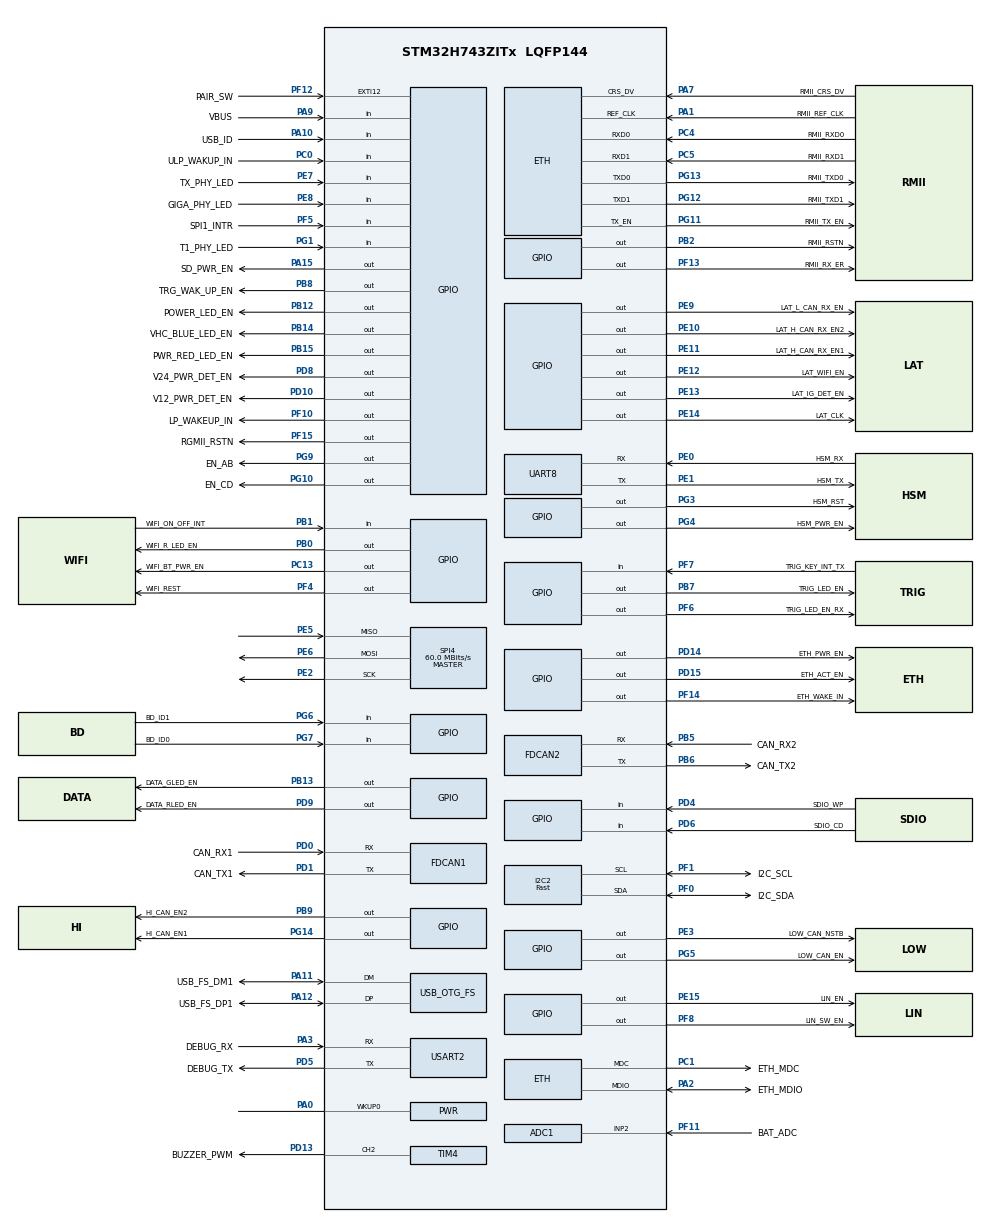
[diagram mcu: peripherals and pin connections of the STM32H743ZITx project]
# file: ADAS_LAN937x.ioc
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PA11.GPIO_Speed=GPIO_SPEED_FREQ_HIGH
IWDG1.Prescaler=IWDG_PRESCALER_16
VP_SYS_VS_tim6.Mode=TIM6
SPI4.VirtualType=VM_MASTER
VP_TIM17_VS_ClockSourceINT.Mode=Enable_Timer
FDCAN2.DataPrescaler=2
NVIC.TIM6_DAC_IRQn=true\:0\:0\:false\:false\:true\:false\:false\:true
PG4.Signal=GPIO_Output
PB14.GPIO_Label=VHC_BLUE_LED_EN
PG6.GPIO_Label=BD_ID1
FDCAN2.RxFifo0ElmtsNbr=32
RCC.PLLFRACN=0
VP_RTC_VS_RTC_Activate.Mode=RTC_Enabled
PB6.GPIO_Label=CAN_TX2
PA15\ (JTDI).Signal=GPIO_Output
PC5.Mode=RMII
PB13.Signal=GPIO_Output
PD6.GPIO_Label=SDIO_CD
PG13.Signal=ETH_TXD0
PF6.GPIO_Label=TRIG_LED_EN_RX
RCC.SYSCLKSource=RCC_SYSCLKSOURCE_PLLCLK
IWDG1.Reload=762
FREERTOS.configENABLE_FPU=1
PA14\ (JTCK/SWCLK).Signal=DEBUG_JTCK-SWCLK
PF7.Signal=GPIO_Input
PE2.Mode=Full_Duplex_Master
PD4.Signal=GPIO_Input
I2C2.I2C_Speed_Mode=I2C_Fast
PB6.Signal=FDCAN2_TX
PB6.Mode=FDCANFD
PD0.Signal=FDCAN1_RX
PD8.Signal=GPIO_Output
PE5.Signal=SPI4_MISO
PE1.Signal=UART8_TX
PF10.GPIO_Label=LP_WAKEUP_IN
PB2.Signal=GPIO_Output
PF1.GPIO_Label=I2C_SCL
RCC.DIVM3=5
RCC.DIVM2=5
RCC.DIVM1=5
RCC.RTCClockSelection=RCC_RTCCLKSOURCE_LSE
PD1.GPIO_Label=CAN_TX1
PB12.GPIO_Label=POWER_LED_EN
PF12.GPIO_Label=PAIR_SW
PC4.GPIO_Label=RMII_RXD0
PE9.Signal=GPIO_Output
PD1.GPIO_Speed=GPIO_SPEED_FREQ_VERY_HIGH
PB1.GPIO_Label=WIFI_ON_OFF_INT
FDCAN1.NominalPrescaler=2
PG4.GPIO_Label=HSM_PWR_EN
PA0.Mode=WakeUp0
SH.S_TIM4_CH2.0=TIM4_CH2,PWM Generation2 CH2
PE2.Signal=SPI4_SCK
PA14\ (JTCK/SWCLK).Mode=Trace_Asynchronous_SW
TIM4.Period=0
VP_FREERTOS_VS_CMSIS_V1.Mode=CMSIS_V1
PF1.GPIO_Speed=GPIO_SPEED_FREQ_HIGH
PE10.Signal=GPIO_Output
ADC1.SamplingTime-0\#ChannelRegularConversion=ADC_SAMPLETIME_1CYCLE_5
PA0.Signal=PWR_WKUP0
Mcu.Package=LQFP144
PB9.Signal=GPIO_Output
PB1.Signal=GPIO_Input
NVIC.TimeBase=TIM6_DAC_IRQn
RCC.PLL3FRACN=0
NVIC.TimeBaseIP=TIM6
PA10.Signal=GPIO_Input
PE12.GPIO_Label=LAT_WIFI_EN
FDCAN2.TxElmtSize=FDCAN_DATA_BYTES_64
PB5.GPIO_Speed=GPIO_SPEED_FREQ_VERY_HIGH
PC14-OSC32_IN\ (OSC32_IN).Mode=LSE-External-Oscillator
RCC.APB4Freq_Value=120000000
FDCAN1.DataTimeSeg2=4
PF14.Signal=GPIO_Output
FDCAN1.DataTimeSeg1=15
RCC.FDCANCLockSelection=RCC_FDCANCLKSOURCE_PLL2
PE10.GPIO_Label=LAT_H_CAN_RX_EN2
PH0-OSC_IN\ (PH0).Mode=HSE-External-Oscillator
PD15.Signal=GPIO_Output
PC4.Mode=RMII
PG12.Signal=ETH_TXD1
RCC.DIVQ3=20
NVIC.UART8_IRQn=true\:5\:0\:true\:false\:true\:true\:true\:true
RCC.DIVQ2=10
FREERTOS.Tasks01=defaultTask,0,128,StartDefaultTask,Default,NULL,Dynamic,NULL,NULL
ADC1.Rank-0\#ChannelRegularConversion=1
PD9.GPIO_Label=DATA_RLED_EN
PG5.Signal=GPIO_Output
ADC1.OffsetNumber-0\#ChannelRegularConversion=ADC_OFFSET_NONE
PG9.Signal=GPIO_Output
PC13.Signal=GPIO_Output
PA9.GPIO_Label=VBUS
PE1.Mode=Asynchronous
PD1.Signal=FDCAN1_TX
PA11.GPIO_Label=USB_FS_DM1
RCC.DIVP2=8
PF14.GPIO_Label=ETH_WAKE_IN
FDCAN1.RxFifo0ElmtSize=FDCAN_DATA_BYTES_64
PC0.Signal=GPIO_Input
PF13.GPIO_Label=RMII_RX_ER
PG13.GPIO_Label=RMII_TXD0
PD0.GPIO_Speed=GPIO_SPEED_FREQ_VERY_HIGH
PG10.Signal=GPIO_Output
NVIC.FDCAN2_IT0_IRQn=true\:5\:0\:true\:false\:true\:true\:true\:true
PF8.GPIO_Label=LIN_SW_EN
PD10.Signal=GPIO_Output
FDCAN2.NominalTimeSeg1=63
PA3.Mode=Asynchronous
FDCAN2.NominalTimeSeg2=16
PF1.Mode=I2C
PF11.Mode=IN2-Single-Ended
PB8.GPIO_Label=TRG_WAK_UP_EN
PE8.GPIO_Label=GIGA_PHY_LED
PA9.Signal=GPIO_Input
RCC.DIVN3=192
RCC.DIVN2=160
RCC.DIVN1=192
FDCAN2.NominalPrescaler=2
NVIC.I2C2_ER_IRQn=true\:5\:0\:true\:false\:true\:false\:true\:true
PE9.GPIO_Label=LAT_L_CAN_RX_EN
ADC1.OffsetSignedSaturation-0\#ChannelRegularConversion=DISABLE
PB14.Signal=GPIO_Output
RCC.USBCLockSelection=RCC_USBCLKSOURCE_PLL3
PE1.GPIO_Label=HSM_TX
PD1.Mode=FDCANFD
FDCAN1.AutoRetransmission=ENABLE
PA1.Mode=RMII
PE14.Signal=GPIO_Output
PE6.Mode=Full_Duplex_Master
PE15.Signal=GPIO_Output
PB15.GPIO_Label=PWR_RED_LED_EN
PE8.Signal=GPIO_Input
PG7.GPIO_Label=BD_ID0
PF4.GPIO_Label=WIFI_REST
PA1.GPIO_Label=RMII_REF_CLK
PF13.Signal=GPIO_Output
PG14.GPIO_Label=HI_CAN_EN1
FDCAN1.DataPrescaler=2
PB5.Signal=FDCAN2_RX
ETH.MediaInterface=HAL_ETH_RMII_MODE
ADC1.master=1
PE13.GPIO_Label=LAT_IG_DET_EN
PG11.Mode=RMII
PA11.Signal=USB_OTG_FS_DM
ProjectManager.HeapSize=0x2000
NVIC.PriorityGroup=NVIC_PRIORITYGROUP_4
FDCAN2.TxFifoQueueElmtsNbr=32
PF0.GPIO_Label=I2C_SDA
PB3\ (JTDO/TRACESWO).Mode=Trace_Asynchronous_SW
PE3.Signal=GPIO_Output
PF4.Signal=GPIO_Output
PG3.GPIO_Label=HSM_RST
PB6.GPIO_Speed=GPIO_SPEED_FREQ_VERY_HIGH
PB0.Signal=GPIO_Output
PC1.Signal=ETH_MDC
PG10.GPIO_Label=EN_CD
PA13\ (JTMS/SWDIO).Signal=DEBUG_JTMS-SWDIO
PC1.Mode=RMII
Mcu.Family=STM32H7
USB_DEVICE.CLASS_NAME_FS=CDC
TIM17.Prescaler=240
RCC.CortexFreq_Value=480000000
PG6.Signal=GPIO_Input
FDCAN1.ExtFiltersNbr=0
RCC.HPRE=RCC_HCLK_DIV2
FDCAN1.DataSyncJumpWidth=1
PH0-OSC_IN\ (PH0).Signal=RCC_OSC_IN
PE11.GPIO_Label=LAT_H_CAN_RX_EN1
PC15-OSC32_OUT\ (OSC32_OUT).Mode=LSE-External-Oscillator
SPI4.Direction=SPI_DIRECTION_2LINES
I2C2.Timing=0x00B03FDB
PC0.GPIO_Label=ULP_WAKUP_IN
PD0.GPIO_Label=CAN_RX1
PA11.Mode=Device_Only
PB0.GPIO_Label=WIFI_R_LED_EN
USB_DEVICE.VirtualMode-CDC_FS=Cdc
RCC.PLL2FRACN=0
PC13.GPIO_Label=WIFI_BT_PWR_EN
NVIC.FDCAN2_IT1_IRQn=true\:5\:0\:true\:false\:true\:true\:true\:true
PB13.GPIO_Label=DATA_GLED_EN
PG5.GPIO_Label=LOW_CAN_EN
PB15.Signal=GPIO_Output
PG11.Signal=ETH_TX_EN
ProjectManager.StackSize=0x2000
PD13.Signal=S_TIM4_CH2
TIM17.AutoReloadPreload=TIM_AUTORELOAD_PRELOAD_ENABLE
PA12.Signal=USB_OTG_FS_DP
SPI4.Mode=SPI_MODE_MASTER
FDCAN2.FrameFormat=FDCAN_FRAME_FD_BRS
IWDG1.Window=400
NVIC.TIM17_IRQn=true\:0\:0\:false\:false\:true\:true\:true\:true
RCC.HCLKFreq_Value=240000000
PF11.GPIO_Label=BAT_ADC
PF12.Signal=GPXTI12
FDCAN1.RxFifo1ElmtSize=FDCAN_DATA_BYTES_64
FDCAN1.FrameFormat=FDCAN_FRAME_FD_BRS
PD5.Mode=Asynchronous
NVIC.ETH_IRQn=true\:5\:0\:true\:false\:true\:true\:true\:true
ADC1.Channel-0\#ChannelRegularConversion=ADC_CHANNEL_2
PH1-OSC_OUT\ (PH1).Mode=HSE-External-Oscillator
USART2.VirtualMode-Asynchronous=VM_ASYNC
TIM17.Period=1000
VP_IWDG1_VS_IWDG.Mode=IWDG_Activate
FDCAN1.StdFiltersNbr=32
PE13.Signal=GPIO_Output
PF7.GPIO_Label=TRIG_KEY_INT_TX
PF11.Signal=ADC1_INP2
PB5.Mode=FDCANFD
PA10.GPIO_Label=USB_ID
PB7.Signal=GPIO_Output
PG13.Mode=RMII
NVIC.FDCAN1_IT1_IRQn=true\:5\:0\:true\:false\:true\:false\:true\:true
FDCAN1.NominalTimeSeg2=16
FREERTOS.configTOTAL_HEAP_SIZE=307200
FDCAN1.NominalTimeSeg1=63
RCC.APB3Freq_Value=120000000
PB7.GPIO_Label=TRIG_LED_EN
PD13.GPIO_Label=BUZZER_PWM
RCC.D1PPRE=RCC_APB3_DIV2
PD5.GPIO_Label=DEBUG_TX
NVIC.OTG_FS_IRQn=true\:7\:0\:true\:false\:true\:true\:true\:true
FDCAN1.RxFifo0ElmtsNbr=32
PA2.GPIO_Label=ETH_MDIO
PF5.GPIO_Label=SPI1_INTR
USB_OTG_FS.VirtualMode=Device_Only
PF8.Signal=GPIO_Output
PE0.GPIO_Label=HSM_RX
PF5.Signal=GPIO_Input
PB5.GPIO_Label=CAN_RX2
PG11.GPIO_Label=RMII_TX_EN
PF0.Signal=I2C2_SDA
PC5.Signal=ETH_RXD1
PE7.Signal=GPIO_Input
PD6.Signal=GPIO_Input
FDCAN2.StdFiltersNbr=32
PA12.GPIO_Speed=GPIO_SPEED_FREQ_HIGH
FDCAN2.RxFifo1ElmtsNbr=32
PA3.Signal=USART2_RX
NVIC.FDCAN1_IT0_IRQn=true\:5\:0\:true\:false\:true\:false\:true\:true
RCC.PLLSourceVirtual=RCC_PLLSOURCE_HSE
CORTEX_M7.CPU_ICache=Enabled
PD15.GPIO_Label=ETH_ACT_EN
PA7.Mode=RMII
PG7.Signal=GPIO_Input
PA13\ (JTMS/SWDIO).Mode=Trace_Asynchronous_SW
PB9.GPIO_Label=HI_CAN_EN2
USB_DEVICE.VirtualModeFS=Cdc_FS
PG3.Signal=GPIO_Output
PG1.Signal=GPIO_Input
PC4.Signal=ETH_RXD0
RCC.D2PPRE2=RCC_APB2_DIV2
RCC.D2PPRE1=RCC_APB1_DIV2
PE14.GPIO_Label=LAT_CLK
PD9.Signal=GPIO_Output
PD5.Signal=USART2_TX
FDCAN1.MessageRAMOffset=0
NVIC.USART2_IRQn=true\:5\:0\:true\:false\:true\:false\:true\:true
PA12.GPIO_Label=USB_FS_DP1
PH1-OSC_OUT\ (PH1).Signal=RCC_OSC_OUT
FDCAN2.RxFifo1ElmtSize=FDCAN_DATA_BYTES_64
PD8.GPIO_Label=V24_PWR_DET_EN
PF0.GPIO_Speed=GPIO_SPEED_FREQ_HIGH
FDCAN2.MessageRAMOffset=1280
PE15.GPIO_Label=LIN_EN
PF6.Signal=GPIO_Output
PB3\ (JTDO/TRACESWO).Signal=DEBUG_JTDO-SWO
ProjectManager.TargetToolchain=EWARM V8
PC15-OSC32_OUT\ (OSC32_OUT).Signal=RCC_OSC32_OUT
VP_USB_DEVICE_VS_USB_DEVICE_CDC_FS.Mode=CDC_FS
FDCAN2.DataTimeSeg1=15
FDCAN2.DataTimeSeg2=4
RCC.USBFreq_Value=48000000
PD10.GPIO_Label=V12_PWR_DET_EN
PE11.Signal=GPIO_Output
PA1.Signal=ETH_REF_CLK
PG9.GPIO_Label=EN_AB
PG14.Signal=GPIO_Output
board=custom
PG12.Mode=RMII
PG1.GPIO_Label=T1_PHY_LED
FDCAN2.RxFifo0ElmtSize=FDCAN_DATA_BYTES_64
FREERTOS.INCLUDE_eTaskGetState=1
TIM4.Channel-PWM\ Generation2\ CH2=TIM_CHANNEL_2
RCC.APB2Freq_Value=120000000
FDCAN1.RxFifo1ElmtsNbr=32
PD4.GPIO_Label=SDIO_WP
PF10.Signal=GPIO_Output
PE5.Mode=Full_Duplex_Master
RCC.ADCFreq_Value=100000000
PC1.GPIO_Label=ETH_MDC
PF15.GPIO_Label=RGMII_RSTN
PF15.Signal=GPIO_Output
SPI4.CalculateBaudRate=60.0 MBits/s
PD14.GPIO_Label=ETH_PWR_EN
PF1.Signal=I2C2_SCL
PE6.Signal=SPI4_MOSI
PA15\ (JTDI).GPIO_Label=SD_PWR_EN
Mcu.Name=STM32H743ZITx
PE0.Signal=UART8_RX
PE7.GPIO_Label=TX_PHY_LED
PD0.Mode=FDCANFD
PE12.Signal=GPIO_Output
PA2.Signal=ETH_MDIO
PD14.Signal=GPIO_Output
RCC.SYSCLKFreq_VALUE=480000000
PA7.GPIO_Label=RMII_CRS_DV
PA12.Mode=Device_Only
PC14-OSC32_IN\ (OSC32_IN).Signal=RCC_OSC32_IN
PC5.GPIO_Label=RMII_RXD1
FDCAN2.AutoRetransmission=ENABLE
PB2.GPIO_Label=RMII_RSTN
PF0.Mode=I2C
PG12.GPIO_Label=RMII_TXD1
NVIC.I2C2_EV_IRQn=true\:5\:0\:true\:false\:true\:false\:true\:true
ADC1.NbrOfConversionFlag=1
PA2.Mode=RMII
PB8.Signal=GPIO_Output
PE3.GPIO_Label=LOW_CAN_NSTB
RCC.D3PPRE=RCC_APB4_DIV2
CORTEX_M7.CPU_DCache=Enabled
RCC.APB1Freq_Value=120000000
ADC1.ClockPrescaler=ADC_CLOCK_ASYNC_DIV4
FDCAN1.TxFifoQueueElmtsNbr=32
PB12.Signal=GPIO_Output
PE0.Mode=Asynchronous
PA3.GPIO_Label=DEBUG_RX
PA7.Signal=ETH_CRS_DV
FDCAN1.TxElmtSize=FDCAN_DATA_BYTES_64

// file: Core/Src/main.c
/* USER CODE BEGIN Header */
/**
  ******************************************************************************
  * @file           : main.c
  * @brief          : Main program body
  ******************************************************************************
  * @attention
  *
  * <h2><center>&copy; Copyright (c) 2020 STMicroelectronics.
  * All rights reserved.</center></h2>
  *
  * This software component is licensed by ST under Ultimate Liberty license
  * SLA0044, the "License"; You may not use this file except in compliance with
  * the License. You may obtain a copy of the License at:
  *                             www.st.com/SLA0044
  *
  ******************************************************************************
  */
/* USER CODE END Header */
#include "main.h"
#include "cmsis_os.h"
#include "adc.h"
#include "eth.h"
#include "fdcan.h"
#include "i2c.h"
#include "iwdg.h"
#include "rtc.h"
#include "spi.h"
#include "tim.h"
#include "usart.h"
#include "usb_device.h"
#include "gpio.h"

void SystemClock_Config(void);
void MX_FREERTOS_Init(void);

/* USER CODE BEGIN 0 */
/**
  * @brief  Configure the MPU attributes as Write Through for Internal SRAM1.
  * @note   The Base Address 0x24000000 is the SRAM1 accessible by the SDIO internal DMA.
  *         The Configured Region Size is 512KB because same as SRAM1 size.
  * @param  None
  * @retval None
  */
static void MPU_Config(void)
{
	MPU_Region_InitTypeDef MPU_InitStruct;

	/* Disable the MPU */
	HAL_MPU_Disable();

	MPU_InitStruct.Enable			= MPU_REGION_ENABLE;
	MPU_InitStruct.BaseAddress		= 0x24000000;
	MPU_InitStruct.Size				= MPU_REGION_SIZE_512KB;
	MPU_InitStruct.AccessPermission	= MPU_REGION_FULL_ACCESS;
	MPU_InitStruct.IsBufferable		= MPU_ACCESS_NOT_BUFFERABLE;
	MPU_InitStruct.IsCacheable		= MPU_ACCESS_CACHEABLE;
	MPU_InitStruct.IsShareable		= MPU_ACCESS_NOT_SHAREABLE;
	MPU_InitStruct.Number			= MPU_REGION_NUMBER0;
	MPU_InitStruct.TypeExtField		= MPU_TEX_LEVEL0;
	MPU_InitStruct.SubRegionDisable	= 0x00;
	MPU_InitStruct.DisableExec		= MPU_INSTRUCTION_ACCESS_ENABLE;

	HAL_MPU_ConfigRegion(&MPU_InitStruct);

	/* Enable the MPU */
	HAL_MPU_Enable(MPU_PRIVILEGED_DEFAULT);
}

/* USER CODE END 0 */

int main(void)
{
  /* USER CODE BEGIN 1 */
	MPU_Config();
  /* USER CODE END 1 */

  /* Enable I-Cache---------------------------------------------------------*/
  SCB_EnableICache();

  /* Enable D-Cache---------------------------------------------------------*/
  SCB_EnableDCache();

  /* MCU Configuration--------------------------------------------------------*/

  /* Reset of all peripherals, Initializes the Flash interface and the Systick. */
  HAL_Init();

  /* Configure the system clock */
  SystemClock_Config();

  /* Initialize all configured peripherals */
  MX_GPIO_Init();
  MX_ADC1_Init();
  MX_RTC_Init();
  MX_I2C2_Init();
  MX_TIM4_Init();
  MX_USART2_UART_Init();
  MX_FDCAN1_Init();
  MX_FDCAN2_Init();
  MX_SPI4_Init();
  MX_UART8_Init();
  MX_ETH_Init();
  MX_TIM17_Init();

  /* Call init function for freertos objects (in freertos.c) */
  MX_FREERTOS_Init();
  /* Start scheduler */
  osKernelStart();

  /* We should never get here as control is now taken by the scheduler */
  /* Infinite loop */
  while (1)
  {

  }
}

void SystemClock_Config(void)
{
  RCC_OscInitTypeDef RCC_OscInitStruct = {0};
  RCC_ClkInitTypeDef RCC_ClkInitStruct = {0};
  RCC_PeriphCLKInitTypeDef PeriphClkInitStruct = {0};

  /** Supply configuration update enable
  */
  HAL_PWREx_ConfigSupply(PWR_LDO_SUPPLY);
  /** Configure the main internal regulator output voltage
  */
  __HAL_PWR_VOLTAGESCALING_CONFIG(PWR_REGULATOR_VOLTAGE_SCALE0);

  while(!__HAL_PWR_GET_FLAG(PWR_FLAG_VOSRDY)) {}
  /** Configure LSE Drive Capability
  */
  HAL_PWR_EnableBkUpAccess();
  __HAL_RCC_LSEDRIVE_CONFIG(RCC_LSEDRIVE_LOW);
  /** Macro to configure the PLL clock source
  */
  __HAL_RCC_PLL_PLLSOURCE_CONFIG(RCC_PLLSOURCE_HSE);
  /** Initializes the RCC Oscillators according to the specified parameters
  * in the RCC_OscInitTypeDef structure.
  */
  RCC_OscInitStruct.OscillatorType = RCC_OSCILLATORTYPE_LSI|RCC_OSCILLATORTYPE_HSE
                              |RCC_OSCILLATORTYPE_LSE;
  RCC_OscInitStruct.HSEState = RCC_HSE_ON;
  RCC_OscInitStruct.LSEState = RCC_LSE_ON;
  RCC_OscInitStruct.LSIState = RCC_LSI_ON;
  RCC_OscInitStruct.PLL.PLLState = RCC_PLL_ON;
  RCC_OscInitStruct.PLL.PLLSource = RCC_PLLSOURCE_HSE;
  RCC_OscInitStruct.PLL.PLLM = 5;
  RCC_OscInitStruct.PLL.PLLN = 192;
  RCC_OscInitStruct.PLL.PLLP = 2;
  RCC_OscInitStruct.PLL.PLLQ = 2;
  RCC_OscInitStruct.PLL.PLLR = 2;
  RCC_OscInitStruct.PLL.PLLRGE = RCC_PLL1VCIRANGE_2;
  RCC_OscInitStruct.PLL.PLLVCOSEL = RCC_PLL1VCOWIDE;
  RCC_OscInitStruct.PLL.PLLFRACN = 0;
  if (HAL_RCC_OscConfig(&RCC_OscInitStruct) != HAL_OK)
  {
    Error_Handler();
  }
  /** Initializes the CPU, AHB and APB buses clocks
  */
  RCC_ClkInitStruct.ClockType = RCC_CLOCKTYPE_HCLK|RCC_CLOCKTYPE_SYSCLK
                              |RCC_CLOCKTYPE_PCLK1|RCC_CLOCKTYPE_PCLK2
                              |RCC_CLOCKTYPE_D3PCLK1|RCC_CLOCKTYPE_D1PCLK1;
  RCC_ClkInitStruct.SYSCLKSource = RCC_SYSCLKSOURCE_PLLCLK;
  RCC_ClkInitStruct.SYSCLKDivider = RCC_SYSCLK_DIV1;
  RCC_ClkInitStruct.AHBCLKDivider = RCC_HCLK_DIV2;
  RCC_ClkInitStruct.APB3CLKDivider = RCC_APB3_DIV2;
  RCC_ClkInitStruct.APB1CLKDivider = RCC_APB1_DIV2;
  RCC_ClkInitStruct.APB2CLKDivider = RCC_APB2_DIV2;
  RCC_ClkInitStruct.APB4CLKDivider = RCC_APB4_DIV2;

  if (HAL_RCC_ClockConfig(&RCC_ClkInitStruct, FLASH_LATENCY_4) != HAL_OK)
  {
    Error_Handler();
  }
  PeriphClkInitStruct.PeriphClockSelection = RCC_PERIPHCLK_RTC|RCC_PERIPHCLK_USART2
                              |RCC_PERIPHCLK_FDCAN|RCC_PERIPHCLK_UART8
                              |RCC_PERIPHCLK_SPI4|RCC_PERIPHCLK_I2C2
                              |RCC_PERIPHCLK_ADC|RCC_PERIPHCLK_USB;
  PeriphClkInitStruct.PLL2.PLL2M = 5;
  PeriphClkInitStruct.PLL2.PLL2N = 160;
  PeriphClkInitStruct.PLL2.PLL2P = 8;
  PeriphClkInitStruct.PLL2.PLL2Q = 10;
  PeriphClkInitStruct.PLL2.PLL2R = 2;
  PeriphClkInitStruct.PLL2.PLL2RGE = RCC_PLL2VCIRANGE_2;
  PeriphClkInitStruct.PLL2.PLL2VCOSEL = RCC_PLL2VCOWIDE;
  PeriphClkInitStruct.PLL2.PLL2FRACN = 0;
  PeriphClkInitStruct.PLL3.PLL3M = 5;
  PeriphClkInitStruct.PLL3.PLL3N = 192;
  PeriphClkInitStruct.PLL3.PLL3P = 2;
  PeriphClkInitStruct.PLL3.PLL3Q = 20;
  PeriphClkInitStruct.PLL3.PLL3R = 2;
  PeriphClkInitStruct.PLL3.PLL3RGE = RCC_PLL3VCIRANGE_2;
  PeriphClkInitStruct.PLL3.PLL3VCOSEL = RCC_PLL3VCOWIDE;
  PeriphClkInitStruct.PLL3.PLL3FRACN = 0;
  PeriphClkInitStruct.Spi45ClockSelection = RCC_SPI45CLKSOURCE_D2PCLK1;
  PeriphClkInitStruct.FdcanClockSelection = RCC_FDCANCLKSOURCE_PLL2;
  PeriphClkInitStruct.Usart234578ClockSelection = RCC_USART234578CLKSOURCE_D2PCLK1;
  PeriphClkInitStruct.I2c123ClockSelection = RCC_I2C123CLKSOURCE_D2PCLK1;
  PeriphClkInitStruct.UsbClockSelection = RCC_USBCLKSOURCE_PLL3;
  PeriphClkInitStruct.AdcClockSelection = RCC_ADCCLKSOURCE_PLL2;
  PeriphClkInitStruct.RTCClockSelection = RCC_RTCCLKSOURCE_LSE;
  if (HAL_RCCEx_PeriphCLKConfig(&PeriphClkInitStruct) != HAL_OK)
  {
    Error_Handler();
  }
  /** Enable USB Voltage detector
  */
  HAL_PWREx_EnableUSBVoltageDetector();
}

void HAL_TIM_PeriodElapsedCallback(TIM_HandleTypeDef *htim)
{
  if (htim->Instance == TIM6) {
    HAL_IncTick();
  }
}

void Error_Handler(void)
{
}

/************************ (C) COPYRIGHT STMicroelectronics *****END OF FILE****/

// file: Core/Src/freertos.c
/* USER CODE BEGIN Header */
/**
  ******************************************************************************
  * File Name          : freertos.c
  * Description        : Code for freertos applications
  ******************************************************************************
  * @attention
  *
  * <h2><center>&copy; Copyright (c) 2020 STMicroelectronics.
  * All rights reserved.</center></h2>
  *
  * This software component is licensed by ST under Ultimate Liberty license
  * SLA0044, the "License"; You may not use this file except in compliance with
  * the License. You may obtain a copy of the License at:
  *                             www.st.com/SLA0044
  *
  ******************************************************************************
  */
/* USER CODE END Header */

#include "FreeRTOS.h"
#include "task.h"
#include "main.h"
#include "cmsis_os.h"

/* USER CODE BEGIN Includes */

#include "common.h"
/* USER CODE END Includes */

osThreadId defaultTaskHandle;

void StartDefaultTask(void const * argument);

extern void MX_USB_DEVICE_Init(void);
void MX_FREERTOS_Init(void); /* (MISRA C 2004 rule 8.1) */

/* GetIdleTaskMemory prototype (linked to static allocation support) */
void vApplicationGetIdleTaskMemory( StaticTask_t **ppxIdleTaskTCBBuffer, StackType_t **ppxIdleTaskStackBuffer, uint32_t *pulIdleTaskStackSize );

/* USER CODE BEGIN GET_IDLE_TASK_MEMORY */
static StaticTask_t xIdleTaskTCBBuffer;
static StackType_t xIdleStack[configMINIMAL_STACK_SIZE];

void vApplicationGetIdleTaskMemory( StaticTask_t **ppxIdleTaskTCBBuffer, StackType_t **ppxIdleTaskStackBuffer, uint32_t *pulIdleTaskStackSize )
{
  *ppxIdleTaskTCBBuffer = &xIdleTaskTCBBuffer;
  *ppxIdleTaskStackBuffer = &xIdleStack[0];
  *pulIdleTaskStackSize = configMINIMAL_STACK_SIZE;
  /* place for user code */
}
/* USER CODE END GET_IDLE_TASK_MEMORY */

void MX_FREERTOS_Init(void) {
  /* USER CODE BEGIN Init */

	GLogI( "==================================================\r\n" );
	GLogI( "   Start Application(%s)...\r\n", __DATE__ );
	GLogI( "==================================================\r\n" );
	getBoardID();
	printCLKs();

  /* USER CODE END Init */

  /* Create the thread(s) */
  /* definition and creation of defaultTask */
  osThreadDef(defaultTask, StartDefaultTask, osPriorityNormal, 0, 128);
  defaultTaskHandle = osThreadCreate(osThread(defaultTask), NULL);

}

void StartDefaultTask(void const * argument)
{
  /* init code for USB_DEVICE */
  MX_USB_DEVICE_Init();
  for(;;)
  {
    osDelay(1);
  }
}

/************************ (C) COPYRIGHT STMicroelectronics *****END OF FILE****/
